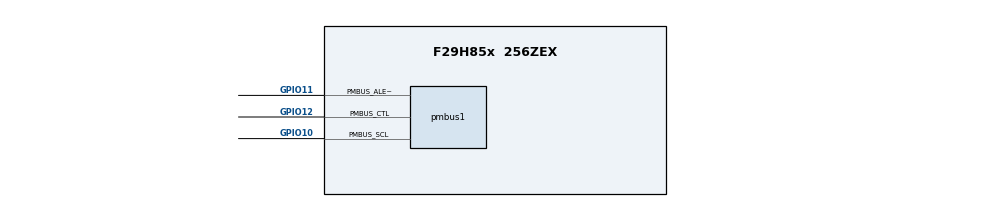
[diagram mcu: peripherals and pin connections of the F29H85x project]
/**
 * @cliArgs --device "F29H85x" --package "256ZEX" --part "F29H85x_256ZEX" --context "CPU1" --product "MCU_SDK_F29H85x@1.02.02.00"
 * @versions {"tool":"1.24.1+4189"}
 */

/**
 * Import the modules used in this configuration.
 */
const gpio   = scripting.addModule("/driverlib/gpio.js", {}, false);
const gpio1  = gpio.addInstance();
const jtag   = scripting.addModule("/driverlib/jtag.js");
const pmbus  = scripting.addModule("/driverlib/pmbus.js", {}, false);
const pmbus1 = pmbus.addInstance();

/**
 * Write custom configuration values to the imported modules.
 */
gpio1.$name = "myGPIO0";


pmbus1.$name                        = "myPMBUS0";
pmbus1.useInterrupts                = true;
pmbus1.registerInterrupts           = true;
pmbus1.enabledInterrupts            = ["PMBUS_INT_ALERT","PMBUS_INT_DATA_READY","PMBUS_INT_EOM"];
pmbus1.busClock                     = "PMBUS_CLOCKMODE_FAST";
pmbus1.pmbus.pmbus_alertPin.$assign = "GPIO11";
pmbus1.pmbus.pmbus_ctlPin.$assign   = "GPIO12";
pmbus1.pmbus.pmbus_sclPin.$assign   = "GPIO10";
pmbus1.BaudRate                   = 9000000;
pmbus1.alertQual.padConfig          = "OD";
pmbus1.ctlQual.padConfig            = "OD";
pmbus1.sclQual.padConfig            = "OD";
pmbus1.sdaQual.padConfig            = "OD";
pmbus1.periphClock.$name            = "driverlib_perClock0";
pmbus1.periphConfig.$name           = "driverlib_perConfig0";
pmbus1.pmbusInt.interruptPriority   = 40;
pmbus1.pmbusInt.contextID           = "INTERRUPT_CONTEXT_AGNOSTIC";

/**
 * Pinmux solution for unlocked pins/peripherals. This ensures that minor changes to the automatic solver in a future
 * version of the tool will not impact the pinmux you originally saw.  These lines can be completely deleted in order to
 * re-solve from scratch.
 */
gpio1.gpioPin.$suggestSolution             = "GPIO15";
jtag.JTAG.$suggestSolution                 = "JTAG";
jtag.JTAG.tdoPin.$suggestSolution          = "GPIO223/TDO";
jtag.JTAG.tdiPin.$suggestSolution          = "GPIO222/TDI";
pmbus1.pmbus.$suggestSolution              = "PMBUSA";
pmbus1.pmbus.pmbus_sdaPin.$suggestSolution = "GPIO22";
